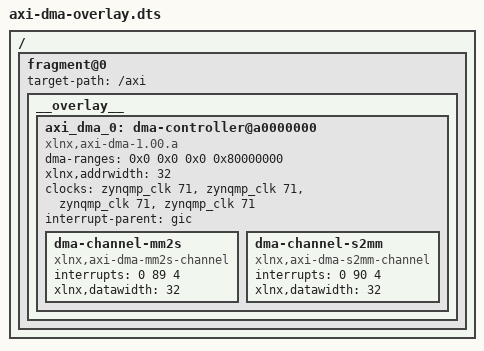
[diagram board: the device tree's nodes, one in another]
/dts-v1/
/plugin/

/ {
	fragment@0 {
		target-path = "/axi";
		
		__overlay__ {
			axi_dma_0: dma-controller@a0000000 {
				compatible = "xlnx,axi-dma-1.00.a"
				reg = <0x0 0xa0000000 0x0 0x10000>;
				
				#dma-cells = <1>;
				#address-cells = <1>;
				#size-cells = <1>;
				
				dma-ranges = <0x0 0x0 0x0 0x80000000>;
				xlnx,addrwidth = <32>;
				
				clocks = <&zynqmp_clk 71>,
						 <&zynqmp_clk 71>,
						 <&zynqmp_clk 71>,
						 <&zynqmp_clk 71>;
						 
				clock-names = "s_axi_lite_aclk",
							  "m_axi_mm2s_aclk",
							  "m_axi_s2mm_aclk",
							  "m_axi_sg_aclk";
							  
				interrupt-parent = <&gic>;
				
				dma-channel-mm2s {
					compatible = "xlnx,axi-dma-mm2s-channel";
					interrupts = <0 89 4>;
					xlnx,datawidth = <32>;
				};
				
				dma-channel-s2mm {
					compatible = "xlnx,axi-dma-s2mm-channel";
					interrupts = <0 90 4>;
					xlnx,datawidth = <32>;
				};
			}
		}
	
	}
}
